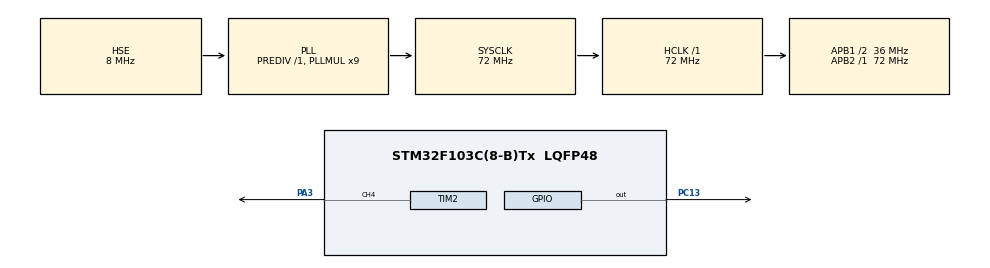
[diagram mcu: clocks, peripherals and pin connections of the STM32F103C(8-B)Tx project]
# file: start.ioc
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Dma.Request0=TIM2_CH2/CH4
Dma.TIM2_CH2/CH4.0.Direction=DMA_MEMORY_TO_PERIPH
Dma.TIM2_CH2/CH4.0.Instance=DMA1_Channel7
Dma.TIM2_CH2/CH4.0.MemDataAlignment=DMA_MDATAALIGN_WORD
Dma.TIM2_CH2/CH4.0.MemInc=DMA_MINC_ENABLE
Dma.TIM2_CH2/CH4.0.Mode=DMA_CIRCULAR
Dma.TIM2_CH2/CH4.0.PeriphDataAlignment=DMA_PDATAALIGN_WORD
Dma.TIM2_CH2/CH4.0.PeriphInc=DMA_PINC_DISABLE
Dma.TIM2_CH2/CH4.0.Priority=DMA_PRIORITY_HIGH
Mcu.Family=STM32F1
Mcu.Name=STM32F103C(8-B)Tx
Mcu.Package=LQFP48
NVIC.DMA1_Channel7_IRQn=true\:0\:0\:false\:false\:true\:false\:true
NVIC.PriorityGroup=NVIC_PRIORITYGROUP_4
NVIC.TIM3_IRQn=true\:0\:0\:false\:false\:true\:true\:true
PA13.Mode=Serial_Wire
PA13.Signal=SYS_JTMS-SWDIO
PA14.Mode=Serial_Wire
PA14.Signal=SYS_JTCK-SWCLK
PA3.GPIO_ModeDefaultPP=GPIO_MODE_AF_OD
PA3.GPIO_Speed=GPIO_SPEED_FREQ_HIGH
PA3.Signal=S_TIM2_CH4
PC13-TAMPER-RTC.Signal=GPIO_Output
PD0-OSC_IN.Mode=HSE-External-Oscillator
PD0-OSC_IN.Signal=RCC_OSC_IN
PD1-OSC_OUT.Mode=HSE-External-Oscillator
PD1-OSC_OUT.Signal=RCC_OSC_OUT
ProjectManager.HeapSize=0x200
ProjectManager.StackSize=0x400
ProjectManager.TargetToolchain=TrueSTUDIO
RCC.AHBFreq_Value=72000000
RCC.APB1CLKDivider=RCC_HCLK_DIV2
RCC.APB1Freq_Value=36000000
RCC.APB1TimFreq_Value=72000000
RCC.APB2Freq_Value=72000000
RCC.APB2TimFreq_Value=72000000
RCC.HCLKFreq_Value=72000000
RCC.PLLMUL=RCC_PLL_MUL9
RCC.PLLSourceVirtual=RCC_PLLSOURCE_HSE
RCC.SYSCLKFreq_VALUE=72000000
RCC.SYSCLKSource=RCC_SYSCLKSOURCE_PLLCLK
RCC.USBFreq_Value=72000000
SH.S_TIM2_CH4.0=TIM2_CH4,PWM Generation4 CH4
TIM2.Channel-PWM\ Generation4\ CH4=TIM_CHANNEL_4
TIM3.Period=9999
TIM3.Prescaler=7199
VP_TIM3_VS_ClockSourceINT.Mode=Internal
board=custom

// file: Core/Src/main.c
/* USER CODE BEGIN Header */
/**
  ******************************************************************************
  * @file           : main.c
  * @brief          : Main program body
  ******************************************************************************
  * @attention
  *
  * <h2><center>&copy; Copyright (c) 2022 STMicroelectronics.
  * All rights reserved.</center></h2>
  *
  * This software component is licensed by ST under BSD 3-Clause license,
  * the "License"; You may not use this file except in compliance with the
  * License. You may obtain a copy of the License at:
  *                        opensource.org/licenses/BSD-3-Clause
  *
  ******************************************************************************
  */
/* USER CODE END Header */
#include "main.h"

/* USER CODE BEGIN Includes */
#include "C:\Users\Андрей\Desktop\STM\start\Core\Lib\app_main.h"
/* USER CODE END Includes */

TIM_HandleTypeDef htim2;
TIM_HandleTypeDef htim3;
DMA_HandleTypeDef hdma_tim2_ch2_ch4;

void SystemClock_Config(void);
static void MX_GPIO_Init(void);
static void MX_DMA_Init(void);
static void MX_TIM3_Init(void);
static void MX_TIM2_Init(void);

int main(void)
{

  /* MCU Configuration--------------------------------------------------------*/

  /* Reset of all peripherals, Initializes the Flash interface and the Systick. */
  HAL_Init();

  /* Configure the system clock */
  SystemClock_Config();

  /* Initialize all configured peripherals */
  MX_GPIO_Init();
  MX_DMA_Init();
  MX_TIM3_Init();
  MX_TIM2_Init();
  /* USER CODE BEGIN 2 */
  HAL_TIM_Base_Start_IT(&htim3);
  app_main();
  /* USER CODE END 2 */

  /* Infinite loop */
  /* USER CODE BEGIN WHILE */
  while (1)
  {

	  /*HAL_Delay (1000); HAL_GPIO_TogglePin(GPIOC, GPIO_PIN_13);*/

    /* USER CODE END WHILE */

  }
}

void SystemClock_Config(void)
{
  RCC_OscInitTypeDef RCC_OscInitStruct = {0};
  RCC_ClkInitTypeDef RCC_ClkInitStruct = {0};

  /** Initializes the RCC Oscillators according to the specified parameters
  * in the RCC_OscInitTypeDef structure.
  */
  RCC_OscInitStruct.OscillatorType = RCC_OSCILLATORTYPE_HSE;
  RCC_OscInitStruct.HSEState = RCC_HSE_ON;
  RCC_OscInitStruct.HSEPredivValue = RCC_HSE_PREDIV_DIV1;
  RCC_OscInitStruct.HSIState = RCC_HSI_ON;
  RCC_OscInitStruct.PLL.PLLState = RCC_PLL_ON;
  RCC_OscInitStruct.PLL.PLLSource = RCC_PLLSOURCE_HSE;
  RCC_OscInitStruct.PLL.PLLMUL = RCC_PLL_MUL9;
  if (HAL_RCC_OscConfig(&RCC_OscInitStruct) != HAL_OK)
  {
    Error_Handler();
  }
  /** Initializes the CPU, AHB and APB buses clocks
  */
  RCC_ClkInitStruct.ClockType = RCC_CLOCKTYPE_HCLK|RCC_CLOCKTYPE_SYSCLK
                              |RCC_CLOCKTYPE_PCLK1|RCC_CLOCKTYPE_PCLK2;
  RCC_ClkInitStruct.SYSCLKSource = RCC_SYSCLKSOURCE_PLLCLK;
  RCC_ClkInitStruct.AHBCLKDivider = RCC_SYSCLK_DIV1;
  RCC_ClkInitStruct.APB1CLKDivider = RCC_HCLK_DIV2;
  RCC_ClkInitStruct.APB2CLKDivider = RCC_HCLK_DIV1;

  if (HAL_RCC_ClockConfig(&RCC_ClkInitStruct, FLASH_LATENCY_2) != HAL_OK)
  {
    Error_Handler();
  }
}

static void MX_TIM2_Init(void)
{

  TIM_MasterConfigTypeDef sMasterConfig = {0};
  TIM_OC_InitTypeDef sConfigOC = {0};

  htim2.Instance = TIM2;
  htim2.Init.Prescaler = 0;
  htim2.Init.CounterMode = TIM_COUNTERMODE_UP;
  htim2.Init.Period = 65535;
  htim2.Init.ClockDivision = TIM_CLOCKDIVISION_DIV1;
  htim2.Init.AutoReloadPreload = TIM_AUTORELOAD_PRELOAD_DISABLE;
  if (HAL_TIM_PWM_Init(&htim2) != HAL_OK)
  {
    Error_Handler();
  }
  sMasterConfig.MasterOutputTrigger = TIM_TRGO_RESET;
  sMasterConfig.MasterSlaveMode = TIM_MASTERSLAVEMODE_DISABLE;
  if (HAL_TIMEx_MasterConfigSynchronization(&htim2, &sMasterConfig) != HAL_OK)
  {
    Error_Handler();
  }
  sConfigOC.OCMode = TIM_OCMODE_PWM1;
  sConfigOC.Pulse = 0;
  sConfigOC.OCPolarity = TIM_OCPOLARITY_HIGH;
  sConfigOC.OCFastMode = TIM_OCFAST_DISABLE;
  if (HAL_TIM_PWM_ConfigChannel(&htim2, &sConfigOC, TIM_CHANNEL_4) != HAL_OK)
  {
    Error_Handler();
  }
  HAL_TIM_MspPostInit(&htim2);

}

static void MX_TIM3_Init(void)
{

  TIM_ClockConfigTypeDef sClockSourceConfig = {0};
  TIM_MasterConfigTypeDef sMasterConfig = {0};

  htim3.Instance = TIM3;
  htim3.Init.Prescaler = 7199;
  htim3.Init.CounterMode = TIM_COUNTERMODE_UP;
  htim3.Init.Period = 9999;
  htim3.Init.ClockDivision = TIM_CLOCKDIVISION_DIV1;
  htim3.Init.AutoReloadPreload = TIM_AUTORELOAD_PRELOAD_DISABLE;
  if (HAL_TIM_Base_Init(&htim3) != HAL_OK)
  {
    Error_Handler();
  }
  sClockSourceConfig.ClockSource = TIM_CLOCKSOURCE_INTERNAL;
  if (HAL_TIM_ConfigClockSource(&htim3, &sClockSourceConfig) != HAL_OK)
  {
    Error_Handler();
  }
  sMasterConfig.MasterOutputTrigger = TIM_TRGO_RESET;
  sMasterConfig.MasterSlaveMode = TIM_MASTERSLAVEMODE_DISABLE;
  if (HAL_TIMEx_MasterConfigSynchronization(&htim3, &sMasterConfig) != HAL_OK)
  {
    Error_Handler();
  }

}

static void MX_DMA_Init(void)
{

  /* DMA controller clock enable */
  __HAL_RCC_DMA1_CLK_ENABLE();

  /* DMA interrupt init */
  /* DMA1_Channel7_IRQn interrupt configuration */
  HAL_NVIC_SetPriority(DMA1_Channel7_IRQn, 0, 0);
  HAL_NVIC_EnableIRQ(DMA1_Channel7_IRQn);

}

static void MX_GPIO_Init(void)
{
  GPIO_InitTypeDef GPIO_InitStruct = {0};

  /* GPIO Ports Clock Enable */
  __HAL_RCC_GPIOC_CLK_ENABLE();
  __HAL_RCC_GPIOD_CLK_ENABLE();
  __HAL_RCC_GPIOA_CLK_ENABLE();

  /*Configure GPIO pin Output Level */
  HAL_GPIO_WritePin(GPIOC, GPIO_PIN_13, GPIO_PIN_RESET);

  /*Configure GPIO pin Output Level */
  HAL_GPIO_WritePin(GPIOA, GPIO_PIN_5, GPIO_PIN_RESET);

  /*Configure GPIO pin : PC13 */
  GPIO_InitStruct.Pin = GPIO_PIN_13;
  GPIO_InitStruct.Mode = GPIO_MODE_OUTPUT_PP;
  GPIO_InitStruct.Pull = GPIO_NOPULL;
  GPIO_InitStruct.Speed = GPIO_SPEED_FREQ_LOW;
  HAL_GPIO_Init(GPIOC, &GPIO_InitStruct);

  /*Configure GPIO pin : PA5 */
  GPIO_InitStruct.Pin = GPIO_PIN_5;
  GPIO_InitStruct.Mode = GPIO_MODE_OUTPUT_PP;
  GPIO_InitStruct.Pull = GPIO_NOPULL;
  GPIO_InitStruct.Speed = GPIO_SPEED_FREQ_LOW;
  HAL_GPIO_Init(GPIOA, &GPIO_InitStruct);

}

void Error_Handler(void)
{
  __disable_irq();
  while (1)
  {
  }
}

/************************ (C) COPYRIGHT STMicroelectronics *****END OF FILE****/
